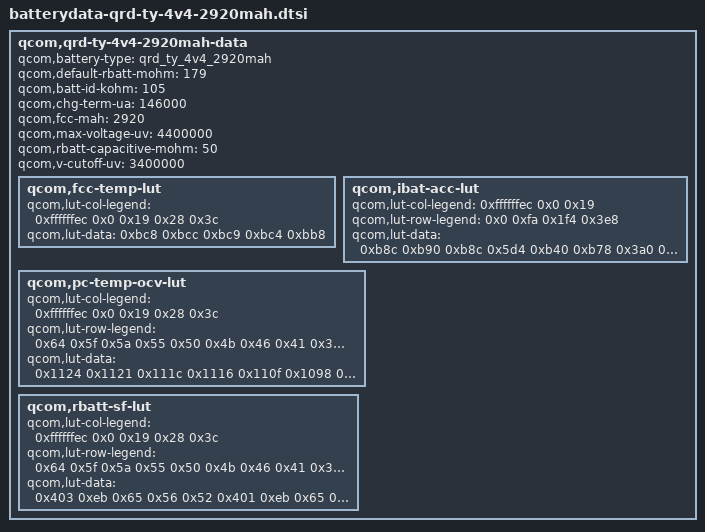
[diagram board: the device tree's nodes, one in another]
/* Copyright (c) 2020, The Linux Foundation. All rights reserved.
*  Copyright (c) 2020, the_shahnawaz_sheikh (sheikhshahnawaz41299).
*
* This program is free software; you can redistribute it and/or modify
* it under the terms of the GNU General Public License version 2 and
* only version 2 as published by the Free Software Foundation.
*
* This program is distributed in the hope that it will be useful,
* but WITHOUT ANY WARRANTY; without even the implied warranty of
* MERCHANTABILITY or FITNESS FOR A PARTICULAR PURPOSE.  See the
* GNU General Public License for more details.
*/

qcom,qrd-ty-4v4-2920mah-data {
			qcom,battery-type = "qrd_ty_4v4_2920mah";
			qcom,default-rbatt-mohm = <179>;
			qcom,batt-id-kohm = <105>;
			qcom,chg-term-ua = <146000>;
			qcom,fcc-mah = <2920>;
			qcom,max-voltage-uv = <4400000>;
			qcom,rbatt-capacitive-mohm = <50>;
			qcom,v-cutoff-uv = <3400000>;

			qcom,fcc-temp-lut {
				qcom,lut-col-legend = <0xffffffec 0x0 0x19 0x28 0x3c>;
				qcom,lut-data = <0xbc8 0xbcc 0xbc9 0xbc4 0xbb8>;
			};

			qcom,ibat-acc-lut {
				qcom,lut-col-legend = <0xffffffec 0x0 0x19>;
				qcom,lut-row-legend = <0x0 0xfa 0x1f4 0x3e8>;
				qcom,lut-data = <0xb8c 0xb90 0xb8c 0x5d4 0xb40 0xb78 0x3a0 0xa5c 0xb62 0x62 0x7ba 0xb23>;
			};

			qcom,pc-temp-ocv-lut {
				qcom,lut-col-legend = <0xffffffec 0x0 0x19 0x28 0x3c>;
				qcom,lut-row-legend = <0x64 0x5f 0x5a 0x55 0x50 0x4b 0x46 0x41 0x3c 0x37 0x32 0x2d 0x28 0x23 0x1e 0x19 0x14 0x10 0xd 0xb 0xa 0x9 0x8 0x7 0x6 0x5 0x4 0x3 0x2 0x1 0x0>;
				qcom,lut-data = <0x1124 0x1121 0x111c 0x1116 0x110f 0x1098 0x10c0 0x10c8 0x10c7 0x10c2 0x1041 0x1080 0x108c 0x108a 0x1085 0xffc 0x1046 0x1052 0x1050 0x104c 0xfc4 0x1010 0x101a 0x1018 0x1014 0xf6c 0xfda 0xfe5 0xfe4 0xfe0 0xf3e 0xf98 0xfb3 0xfb3 0xfb0 0xf12 0xf60 0xf86 0xf87 0xf84 0xef4 0xf38 0xf58 0xf5c 0xf5b 0xee0 0xf16 0xf27 0xf2d 0xf2e 0xed1 0xef8 0xf04 0xf06 0xf05 0xec3 0xee0 0xeec 0xeec 0xeec 0xeb5 0xecd 0xed8 0xed9 0xed8 0xea5 0xec0 0xec8 0xec8 0xec7 0xe96 0xeb5 0xebb 0xeba 0xeb4 0xe86 0xea6 0xeae 0xea8 0xe9c 0xe76 0xe90 0xe9c 0xe95 0xe87 0xe64 0xe7c 0xe86 0xe7e 0xe71 0xe55 0xe70 0xe6d 0xe66 0xe5b 0xe44 0xe6a 0xe66 0xe60 0xe55 0xe3b 0xe66 0xe64 0xe5e 0xe54 0xe2f 0xe62 0xe63 0xe5e 0xe53 0xe22 0xe5e 0xe62 0xe5c 0xe51 0xe10 0xe59 0xe5e 0xe5a 0xe4e 0xdfc 0xe4f 0xe58 0xe54 0xe46 0xde2 0xe3b 0xe45 0xe3c 0xe2a 0xdbc 0xe14 0xe18 0xe0e 0xdfc 0xd86 0xdd4 0xddb 0xdce 0xdbc 0xd31 0xd7b 0xd7f 0xd78 0xd66 0xca8 0xcec 0xcf6 0xcf6 0xce1 0xbb8 0xbb8 0xbb8 0xbb8 0xbb8>;
			};

			qcom,rbatt-sf-lut {
				qcom,lut-col-legend = <0xffffffec 0x0 0x19 0x28 0x3c>;
				qcom,lut-row-legend = <0x64 0x5f 0x5a 0x55 0x50 0x4b 0x46 0x41 0x3c 0x37 0x32 0x2d 0x28 0x23 0x1e 0x19 0x14 0x10 0xd 0xb 0xa 0x9 0x8 0x7 0x6 0x5 0x4 0x3 0x2 0x1 0x0>;
				qcom,lut-data = <0x403 0xeb 0x65 0x56 0x52 0x401 0xeb 0x65 0x56 0x52 0x3b9 0xed 0x63 0x56 0x52 0x37f 0xed 0x65 0x58 0x52 0x35b 0xee 0x67 0x58 0x53 0x307 0xf1 0x6b 0x5b 0x54 0x2f8 0xdd 0x71 0x5e 0x55 0x2e6 0xcb 0x78 0x62 0x58 0x2e6 0xc8 0x76 0x67 0x5b 0x2f9 0xc5 0x67 0x61 0x5a 0x31c 0xc5 0x61 0x57 0x53 0x348 0xc6 0x61 0x57 0x53 0x37b 0xc7 0x63 0x58 0x54 0x3b5 0xd2 0x63 0x5b 0x55 0x3f3 0xe6 0x64 0x59 0x55 0x438 0x100 0x65 0x57 0x53 0x487 0x11a 0x66 0x58 0x53 0x4c2 0x12f 0x67 0x58 0x53 0x48d 0x132 0x65 0x57 0x53 0x4c7 0x143 0x65 0x57 0x53 0x4ed 0x151 0x66 0x58 0x53 0x51a 0x162 0x69 0x59 0x54 0x54e 0x179 0x6c 0x5b 0x56 0x5b4 0x192 0x6f 0x5c 0x58 0x663 0x1ad 0x74 0x5e 0x58 0x772 0x1cb 0x75 0x5d 0x56 0x912 0x1e9 0x75 0x5d 0x56 0xba3 0x221 0x7c 0x60 0x58 0x10e6 0x27c 0x8b 0x68 0x60 0x21cb 0x43d 0xfb 0x8c 0x72 0x4397 0x87a 0x1f6 0x118 0xe4>;
			};
		};

